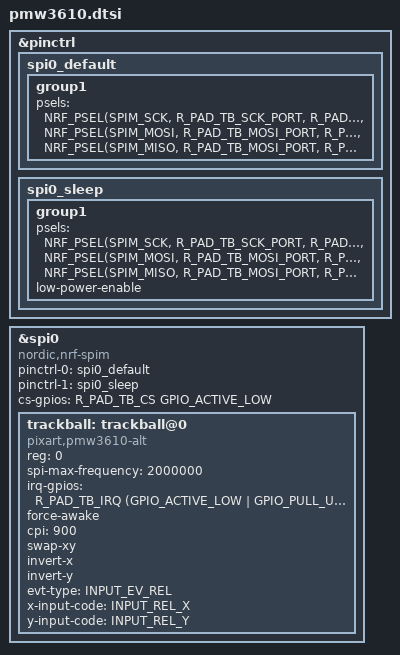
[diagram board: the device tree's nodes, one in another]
#include <zephyr/dt-bindings/input/input-event-codes.h>

/*
 * Trackball pin defaults — overridden by breakout_right.dtsi when the
 * right overlay includes it first. Left overlay disables &spi0 and
 * &trackball, so these defaults are inert there but must still resolve
 * for the dts compile to succeed.
 *
 * SCK / MOSI are SPI pinctrl (NRF_PSEL) -> literal _PORT + _PIN ints.
 * CS / IRQ are plain GPIO -> full `&gpioX pin` spec (raw-nRF, same form
 * as the matrix pads in breakout_*.dtsi). A port-1 trackball needs only
 * `&gpio1 xx` in the breakout file — no edit here.
 */
#ifndef R_PAD_TB_SCK_PORT
  #define R_PAD_TB_SCK_PORT    0
#endif
#ifndef R_PAD_TB_SCK_PIN
  #define R_PAD_TB_SCK_PIN     8
#endif
#ifndef R_PAD_TB_MOSI_PORT
  #define R_PAD_TB_MOSI_PORT   0
#endif
#ifndef R_PAD_TB_MOSI_PIN
  #define R_PAD_TB_MOSI_PIN   17
#endif
#ifndef R_PAD_TB_CS
  #define R_PAD_TB_CS   &gpio0 20
#endif
#ifndef R_PAD_TB_IRQ
  #define R_PAD_TB_IRQ  &gpio0 6
#endif

&pinctrl {
    spi0_default: spi0_default {
        group1 {
            psels = <NRF_PSEL(SPIM_SCK,  R_PAD_TB_SCK_PORT,  R_PAD_TB_SCK_PIN)>,
                <NRF_PSEL(SPIM_MOSI, R_PAD_TB_MOSI_PORT, R_PAD_TB_MOSI_PIN)>,
                <NRF_PSEL(SPIM_MISO, R_PAD_TB_MOSI_PORT, R_PAD_TB_MOSI_PIN)>;
        };
    };

    spi0_sleep: spi0_sleep {
        group1 {
            psels = <NRF_PSEL(SPIM_SCK,  R_PAD_TB_SCK_PORT,  R_PAD_TB_SCK_PIN)>,
                <NRF_PSEL(SPIM_MOSI, R_PAD_TB_MOSI_PORT, R_PAD_TB_MOSI_PIN)>,
                <NRF_PSEL(SPIM_MISO, R_PAD_TB_MOSI_PORT, R_PAD_TB_MOSI_PIN)>;
            low-power-enable;
        };
    };
};

&spi0 {
    status = "okay";
    compatible = "nordic,nrf-spim";
    pinctrl-0 = <&spi0_default>;
    pinctrl-1 = <&spi0_sleep>;
    pinctrl-names = "default", "sleep";
    cs-gpios = <R_PAD_TB_CS GPIO_ACTIVE_LOW>;

    trackball: trackball@0 {
        status = "okay";
        compatible = "pixart,pmw3610-alt";
        reg = <0>;
        spi-max-frequency = <2000000>;
        irq-gpios = <R_PAD_TB_IRQ (GPIO_ACTIVE_LOW | GPIO_PULL_UP)>;

        /* DIAGNOSTIC (2026-07-28, TEMPORARY — revert after the hang test):
         * Force the sensor permanently awake (never downshift to REST), so its
         * SPI clock is always on. Tests the leading hang hypothesis: a rest->wake
         * motion read issued while the sensor's SPI clock is still gated returns
         * stale data and never clears the level-triggered MOTION line -> ISR-level
         * storm the work-queue backoff fix can't see (no counters logged). If the
         * hang STOPS with this set, that path is confirmed; if it persists, the
         * trackball is cleared and the culprit is elsewhere (build the
         * zero-latency WDT PC capture next). Boot log will show
         * "Set performance register (reg value 0xf.)" / "enable performance mode"
         * as confirmation it is active. Costs battery (never sleeps) — debug only. */
        force-awake;

        /* Use this value to change the trackball sensitivity */
        cpi = <900>;

        /* The below settings work best for the Charybdis sensor orientation */
            swap-xy;
            invert-x;
            invert-y;

        evt-type = <INPUT_EV_REL>;
        x-input-code = <INPUT_REL_X>;
        y-input-code = <INPUT_REL_Y>;
    };
};
